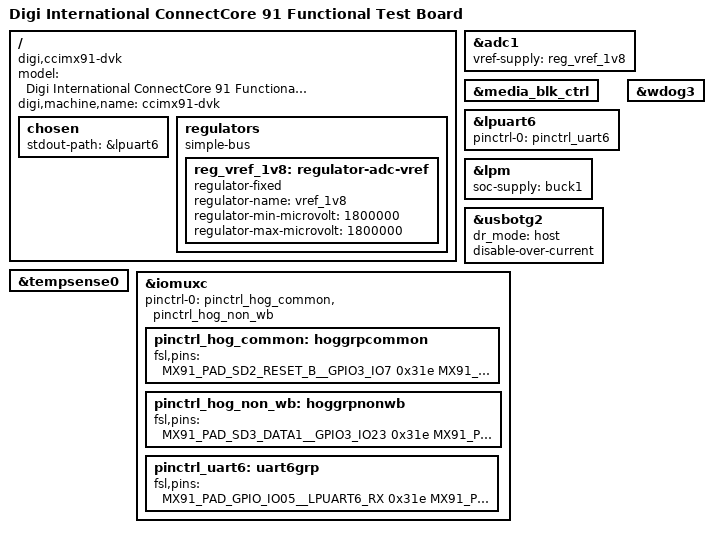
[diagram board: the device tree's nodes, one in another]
/*
 * Copyright (C) 2024, Digi International Inc.
 *
 * Permission to use, copy, modify, and/or distribute this software for any
 * purpose with or without fee is hereby granted, provided that the above
 * copyright notice and this permission notice appear in all copies.
 * THE SOFTWARE IS PROVIDED "AS IS" AND THE AUTHOR DISCLAIMS ALL WARRANTIES
 * WITH REGARD TO THIS SOFTWARE INCLUDING ALL IMPLIED WARRANTIES OF
 * MERCHANTABILITY AND FITNESS. IN NO EVENT SHALL THE AUTHOR BE LIABLE FOR
 * ANY SPECIAL, DIRECT, INDIRECT, OR CONSEQUENTIAL DAMAGES OR ANY DAMAGES
 * WHATSOEVER RESULTING FROM LOSS OF USE, DATA OR PROFITS, WHETHER IN AN
 * ACTION OF CONTRACT, NEGLIGENCE OR OTHER TORTIOUS ACTION, ARISING OUT OF
 * OR IN CONNECTION WITH THE USE OR PERFORMANCE OF THIS SOFTWARE.
 */

/dts-v1/;

#include <dt-bindings/usb/pd.h>
#include "../freescale/imx91.dtsi"

/* Digi ConnectCore 91 (SOM) */
#include "ccimx91.dtsi"

/ {
	model = "Digi International ConnectCore 91 Functional Test Board";
	compatible = "digi,ccimx91-dvk", "digi,ccimx91", "fsl,imx91";
	digi,machine,name = "ccimx91-dvk";

	chosen {
		stdout-path = &lpuart6;
	};

	regulators {
		compatible = "simple-bus";
		#address-cells = <1>;
		#size-cells = <0>;

		reg_vref_1v8: regulator-adc-vref {
			compatible = "regulator-fixed";
			regulator-name = "vref_1v8";
			regulator-min-microvolt = <1800000>;
			regulator-max-microvolt = <1800000>;
		};
	};
};

/* ADC - 4 channels available on expansion connector */
&adc1 {
	vref-supply = <&reg_vref_1v8>;
	status = "okay";
};

&media_blk_ctrl {
	status = "okay";
};

&lpuart6 { /* console */
	pinctrl-names = "default";
	pinctrl-0 = <&pinctrl_uart6>;
	status = "okay";
};

&lpm {
	soc-supply = <&buck1>;
	status = "okay";
};

/* USB_OTG2 connected to usb hub */
&usbotg2 {
	dr_mode = "host";
	disable-over-current;
	status = "okay";
};

&wdog3 {
	status = "okay";
};

&tempsense0 {
	status = "okay";
};

&iomuxc {
	pinctrl-names = "default";
	pinctrl-0 = <&pinctrl_hog_common>, <&pinctrl_hog_non_wb>;
	pinctrl_hog_common: hoggrpcommon {
		fsl,pins = <
			/* 3.3V pairs */
			MX91_PAD_SD2_RESET_B__GPIO3_IO7			0x31e
			MX91_PAD_SD2_CD_B__GPIO3_IO0			0x31e

			MX91_PAD_SD2_DATA0__GPIO3_IO3			0x31e
			MX91_PAD_GPIO_IO00__GPIO2_IO0			0x31e

			MX91_PAD_SD2_DATA1__GPIO3_IO4			0x31e
			MX91_PAD_I2C2_SCL__GPIO1_IO2			0x31e

			MX91_PAD_SD2_DATA3__GPIO3_IO6			0x31e
			MX91_PAD_GPIO_IO01__GPIO2_IO1			0x31e

			MX91_PAD_GPIO_IO08__GPIO2_IO8			0x31e
			MX91_PAD_PDM_BIT_STREAM0__GPIO1_IO9		0x31e

			MX91_PAD_GPIO_IO09__GPIO2_IO9			0x31e
			MX91_PAD_GPIO_IO27__GPIO2_IO27			0x31e

			MX91_PAD_GPIO_IO10__GPIO2_IO10			0x31e
			MX91_PAD_GPIO_IO25__GPIO2_IO25			0x31e

			MX91_PAD_SD2_CMD__GPIO3_IO2			0x31e
			MX91_PAD_I2C2_SDA__GPIO1_IO3			0x31e

			MX91_PAD_SD2_DATA2__GPIO3_IO5			0x31e
			MX91_PAD_GPIO_IO14__GPIO2_IO14			0x31e

			MX91_PAD_SD2_CLK__GPIO3_IO1			0x31e
			MX91_PAD_GPIO_IO12__GPIO2_IO12			0x31e

			MX91_PAD_GPIO_IO11__GPIO2_IO11			0x31e
			MX91_PAD_PDM_CLK__GPIO1_IO8			0x31e

			MX91_PAD_PDM_BIT_STREAM1__GPIO1_IO10		0x31e
			MX91_PAD_SAI1_RXD0__GPIO1_IO14			0x31e

			MX91_PAD_GPIO_IO18__GPIO2_IO18			0x31e
			MX91_PAD_SAI1_TXFS__GPIO1_IO11			0x31e

			MX91_PAD_GPIO_IO22__GPIO2_IO22			0x31e
			MX91_PAD_GPIO_IO15__GPIO2_IO15			0x31e

			MX91_PAD_GPIO_IO24__GPIO2_IO24			0x31e
			MX91_PAD_GPIO_IO13__GPIO2_IO13			0x31e

			MX91_PAD_GPIO_IO06__GPIO2_IO6			0x31e
			MX91_PAD_SAI1_TXD0__GPIO1_IO13			0x31e

			MX91_PAD_GPIO_IO19__GPIO2_IO19			0x31e
			MX91_PAD_SAI1_TXC__GPIO1_IO12			0x31e

			MX91_PAD_GPIO_IO16__GPIO2_IO16			0x31e
			MX91_PAD_GPIO_IO20__GPIO2_IO20			0x31e

			MX91_PAD_SD2_VSELECT__GPIO3_IO19		0x31e
			MX91_PAD_GPIO_IO26__GPIO2_IO26			0x31e

			/* 1.8V pairs */
			MX91_PAD_ENET2_MDIO__GPIO4_IO15			0x31e
			MX91_PAD_CCM_CLKO1__GPIO3_IO26			0x31e

			MX91_PAD_CCM_CLKO4__GPIO4_IO29			0x31e
			MX91_PAD_ENET2_MDC__GPIO4_IO14			0x31e

			MX91_PAD_CCM_CLKO3__GPIO4_IO28			0x31e
			MX91_PAD_CCM_CLKO2__GPIO3_IO27			0x31e

			MX91_PAD_ENET1_MDC__GPIO4_IO0			0x31e
			MX91_PAD_ENET1_MDIO__GPIO4_IO1			0x31e

			MX91_PAD_ENET1_TXC__GPIO4_IO7			0x31e
			MX91_PAD_ENET2_TXC__GPIO4_IO21			0x31e

			MX91_PAD_ENET1_RXC__GPIO4_IO9			0x31e
			MX91_PAD_ENET2_RXC__GPIO4_IO23			0x31e

			MX91_PAD_ENET1_TX_CTL__GPIO4_IO6		0x31e
			MX91_PAD_ENET2_TX_CTL__GPIO4_IO20		0x31e

			MX91_PAD_ENET1_TD1__GPIO4_IO4			0x31e
			MX91_PAD_ENET2_TD1__GPIO4_IO18			0x31e

			MX91_PAD_ENET1_TD3__GPIO4_IO2			0x31e
			MX91_PAD_ENET2_TD3__GPIO4_IO16			0x31e

			MX91_PAD_ENET1_RD0__GPIO4_IO10			0x31e
			MX91_PAD_ENET2_RD0__GPIO4_IO24			0x31e

			MX91_PAD_ENET1_RD2__GPIO4_IO12			0x31e
			MX91_PAD_ENET2_RD2__GPIO4_IO26			0x31e

			MX91_PAD_ENET1_RX_CTL__GPIO4_IO8		0x31e
			MX91_PAD_ENET2_RX_CTL__GPIO4_IO22		0x31e

			MX91_PAD_ENET1_TD0__GPIO4_IO5			0x31e
			MX91_PAD_ENET2_TD0__GPIO4_IO19			0x31e

			MX91_PAD_ENET1_TD2__GPIO4_IO3			0x31e
			MX91_PAD_ENET2_TD2__GPIO4_IO17			0x31e

			MX91_PAD_ENET1_RD1__GPIO4_IO11			0x31e
			MX91_PAD_ENET2_RD1__GPIO4_IO25			0x31e

			MX91_PAD_ENET1_RD3__GPIO4_IO13			0x31e
			MX91_PAD_ENET2_RD3__GPIO4_IO27			0x31e
		>;
	};

	pinctrl_hog_non_wb: hoggrpnonwb {
		fsl,pins = <
			/* Wifi */
			MX91_PAD_SD3_DATA1__GPIO3_IO23				0x31e
			MX91_PAD_SD3_CLK__GPIO3_IO20				0x31e

			MX91_PAD_SD3_DATA2__GPIO3_IO24				0x31e
			MX91_PAD_SD3_CMD__GPIO3_IO21				0x31e

			MX91_PAD_SD3_DATA3__GPIO3_IO25				0x31e
			MX91_PAD_SD3_DATA0__GPIO3_IO22				0x31e

			/* BT uart */
			MX91_PAD_UART1_TXD__GPIO1_IO5				0x31e
			MX91_PAD_UART1_RXD__GPIO1_IO4				0x31e

			MX91_PAD_UART2_TXD__GPIO1_IO7				0x31e
			MX91_PAD_UART2_RXD__GPIO1_IO6				0x31e
		>;
	};

	/* Serial console */
	pinctrl_uart6: uart6grp {
		fsl,pins = <
			MX91_PAD_GPIO_IO05__LPUART6_RX			0x31e
			MX91_PAD_GPIO_IO04__LPUART6_TX			0x31e
		>;
	};
};
